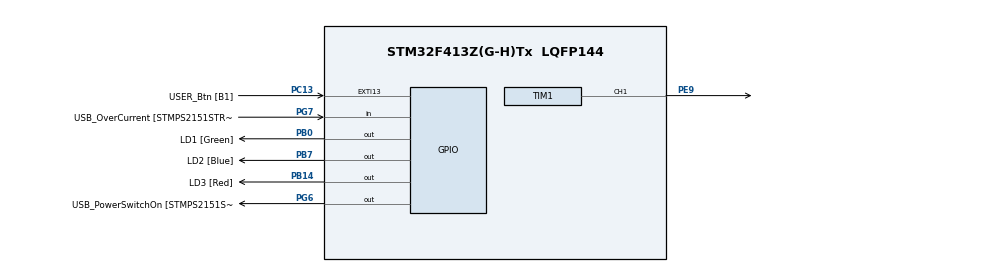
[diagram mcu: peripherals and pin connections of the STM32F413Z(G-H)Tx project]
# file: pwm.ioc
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Mcu.Family=STM32F4
Mcu.Name=STM32F413Z(G-H)Tx
Mcu.Package=LQFP144
NVIC.PriorityGroup=NVIC_PRIORITYGROUP_4
PA10.GPIO_Label=USB_ID
PA10.Signal=USB_OTG_FS_ID
PA11.GPIO_Label=USB_DM
PA11.Signal=USB_OTG_FS_DM
PA12.GPIO_Label=USB_DP
PA12.Signal=USB_OTG_FS_DP
PA13.GPIO_Label=TMS
PA13.Mode=Trace_Asynchronous_SW
PA13.Signal=SYS_JTMS-SWDIO
PA14.GPIO_Label=TCK
PA14.Mode=Trace_Asynchronous_SW
PA14.Signal=SYS_JTCK-SWCLK
PA8.GPIO_Label=USB_SOF [TP1]
PA8.Signal=USB_OTG_FS_SOF
PA9.GPIO_Label=USB_VBUS
PA9.Signal=USB_OTG_FS_VBUS
PB0.GPIO_Label=LD1 [Green]
PB0.Signal=GPIO_Output
PB14.GPIO_Label=LD3 [Red]
PB14.Signal=GPIO_Output
PB3.GPIO_Label=SWO
PB3.Mode=Trace_Asynchronous_SW
PB3.Signal=SYS_JTDO-SWO
PB7.GPIO_Label=LD2 [Blue]
PB7.Signal=GPIO_Output
PC13.GPIO_Label=USER_Btn [B1]
PC13.Signal=GPXTI13
PC14-OSC32_IN.Signal=RCC_OSC32_IN
PC15-OSC32_OUT.Signal=RCC_OSC32_OUT
PD8.GPIO_Label=STLK_RX [STM32F103CBT6_PA3]
PD8.Signal=USART3_TX
PD9.GPIO_Label=STLK_TX [STM32F103CBT6_PA2]
PD9.Signal=USART3_RX
PE9.Signal=S_TIM1_CH1
PG6.GPIO_Label=USB_PowerSwitchOn [STMPS2151STR_EN]
PG6.Signal=GPIO_Output
PG7.GPIO_Label=USB_OverCurrent [STMPS2151STR_FAULT]
PG7.Signal=GPIO_Input
PH0\ -\ OSC_IN.GPIO_Label=MCO
PH0\ -\ OSC_IN.Mode=HSE-External-Oscillator
PH0\ -\ OSC_IN.Signal=RCC_OSC_IN
PH1\ -\ OSC_OUT.Mode=HSE-External-Oscillator
PH1\ -\ OSC_OUT.Signal=RCC_OSC_OUT
ProjectManager.HeapSize=0x2000
ProjectManager.StackSize=0x4000
ProjectManager.TargetToolchain=EWARM V8.32
RCC.48MHZClocksFreq_Value=24000000
RCC.AHBFreq_Value=100000000
RCC.APB1CLKDivider=RCC_HCLK_DIV2
RCC.APB1Freq_Value=50000000
RCC.APB1TimFreq_Value=100000000
RCC.APB2Freq_Value=100000000
RCC.APB2TimFreq_Value=100000000
RCC.CortexFreq_Value=100000000
RCC.HCLKFreq_Value=100000000
RCC.HSE_VALUE=8000000
RCC.HSI_VALUE=16000000
RCC.PLLM=4
RCC.PLLMUL=RCC_PLL_MUL9
RCC.PLLN=100
RCC.PLLSourceVirtual=RCC_PLLSOURCE_HSE
RCC.PRESCALERUSB=RCC_USBCLKSOURCE_PLL_DIV1_5
RCC.SYSCLKFreq_VALUE=100000000
RCC.SYSCLKSource=RCC_SYSCLKSOURCE_PLLCLK
RCC.SYSCLKSourceVirtual=RCC_SYSCLKSOURCE_PLLCLK
RCC.USBFreq_Value=100000000
RCC.VCOOutputFreq_Value=200000000
SH.S_TIM1_CH1.0=TIM1_CH1,PWM Generation1 CH1
TIM1.Channel-PWM\ Generation1\ CH1=TIM_CHANNEL_1
TIM1.Period=9999
TIM1.Prescaler=199
VP_TIM1_VS_ClockSourceINT.Mode=Internal
board=NUCLEO-F413ZH

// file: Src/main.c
/* USER CODE BEGIN Header */
/**
  ******************************************************************************
  * @file           : main.c
  * @brief          : Main program body
  ******************************************************************************
  * @attention
  *
  * <h2><center>&copy; Copyright (c) 2020 STMicroelectronics.
  * All rights reserved.</center></h2>
  *
  * This software component is licensed by ST under BSD 3-Clause license,
  * the "License"; You may not use this file except in compliance with the
  * License. You may obtain a copy of the License at:
  *                        opensource.org/licenses/BSD-3-Clause
  *
  ******************************************************************************
  */
/* USER CODE END Header */

#include "main.h"

void SystemClock_Config(void);
static void MX_GPIO_Init(void);
static void MX_TIM1_Init(void);

int main(void)
{

  /* MCU Configuration--------------------------------------------------------*/

  /* Reset of all peripherals, Initializes the Flash interface and the Systick. */

  LL_APB2_GRP1_EnableClock(LL_APB2_GRP1_PERIPH_SYSCFG);
  LL_APB1_GRP1_EnableClock(LL_APB1_GRP1_PERIPH_PWR);

  NVIC_SetPriorityGrouping(NVIC_PRIORITYGROUP_4);

  /* System interrupt init*/

  /* Configure the system clock */
  SystemClock_Config();

  /* Initialize all configured peripherals */
  MX_GPIO_Init();
  MX_TIM1_Init();
  /* USER CODE BEGIN 2 */
  LL_TIM_CC_EnableChannel(TIM1, LL_TIM_CHANNEL_CH1);
  LL_TIM_EnableCounter(TIM1);
  LL_TIM_EnableAllOutputs(TIM1);
  /* USER CODE END 2 */

  /* Infinite loop */
  while (1)
  {

    /* USER CODE BEGIN 3 */
    LL_TIM_OC_SetCompareCH1(TIM1, 249);
    LL_mDelay(1000);
    LL_TIM_OC_SetCompareCH1(TIM1, 1199);
    LL_mDelay(1000);
  }
  /* USER CODE END 3 */
}

void SystemClock_Config(void)
{
  LL_FLASH_SetLatency(LL_FLASH_LATENCY_3);

  if(LL_FLASH_GetLatency() != LL_FLASH_LATENCY_3)
  {
  Error_Handler();
  }
  LL_PWR_SetRegulVoltageScaling(LL_PWR_REGU_VOLTAGE_SCALE1);
  LL_RCC_HSE_Enable();

   /* Wait till HSE is ready */
  while(LL_RCC_HSE_IsReady() != 1)
  {

  }
  LL_RCC_PLL_ConfigDomain_SYS(LL_RCC_PLLSOURCE_HSE, LL_RCC_PLLM_DIV_4, 100, LL_RCC_PLLP_DIV_2);
  LL_RCC_PLL_Enable();

   /* Wait till PLL is ready */
  while(LL_RCC_PLL_IsReady() != 1)
  {

  }
  LL_RCC_SetAHBPrescaler(LL_RCC_SYSCLK_DIV_1);
  LL_RCC_SetAPB1Prescaler(LL_RCC_APB1_DIV_2);
  LL_RCC_SetAPB2Prescaler(LL_RCC_APB2_DIV_1);
  LL_RCC_SetSysClkSource(LL_RCC_SYS_CLKSOURCE_PLL);

   /* Wait till System clock is ready */
  while(LL_RCC_GetSysClkSource() != LL_RCC_SYS_CLKSOURCE_STATUS_PLL)
  {

  }
  LL_Init1msTick(100000000);
  LL_SYSTICK_SetClkSource(LL_SYSTICK_CLKSOURCE_HCLK);
  LL_SetSystemCoreClock(100000000);
  LL_RCC_SetTIMPrescaler(LL_RCC_TIM_PRESCALER_TWICE);
}

static void MX_TIM1_Init(void)
{

  LL_TIM_InitTypeDef TIM_InitStruct = {0};
  LL_TIM_OC_InitTypeDef TIM_OC_InitStruct = {0};
  LL_TIM_BDTR_InitTypeDef TIM_BDTRInitStruct = {0};

  LL_GPIO_InitTypeDef GPIO_InitStruct = {0};

  /* Peripheral clock enable */
  LL_APB2_GRP1_EnableClock(LL_APB2_GRP1_PERIPH_TIM1);

  TIM_InitStruct.Prescaler = 199;
  TIM_InitStruct.CounterMode = LL_TIM_COUNTERMODE_UP;
  TIM_InitStruct.Autoreload = 9999;
  TIM_InitStruct.ClockDivision = LL_TIM_CLOCKDIVISION_DIV1;
  TIM_InitStruct.RepetitionCounter = 0;
  LL_TIM_Init(TIM1, &TIM_InitStruct);
  LL_TIM_DisableARRPreload(TIM1);
  LL_TIM_SetClockSource(TIM1, LL_TIM_CLOCKSOURCE_INTERNAL);
  LL_TIM_OC_EnablePreload(TIM1, LL_TIM_CHANNEL_CH1);
  TIM_OC_InitStruct.OCMode = LL_TIM_OCMODE_PWM1;
  TIM_OC_InitStruct.OCState = LL_TIM_OCSTATE_DISABLE;
  TIM_OC_InitStruct.OCNState = LL_TIM_OCSTATE_DISABLE;
  TIM_OC_InitStruct.CompareValue = 0;
  TIM_OC_InitStruct.OCPolarity = LL_TIM_OCPOLARITY_HIGH;
  TIM_OC_InitStruct.OCNPolarity = LL_TIM_OCPOLARITY_HIGH;
  TIM_OC_InitStruct.OCIdleState = LL_TIM_OCIDLESTATE_LOW;
  TIM_OC_InitStruct.OCNIdleState = LL_TIM_OCIDLESTATE_LOW;
  LL_TIM_OC_Init(TIM1, LL_TIM_CHANNEL_CH1, &TIM_OC_InitStruct);
  LL_TIM_OC_DisableFast(TIM1, LL_TIM_CHANNEL_CH1);
  LL_TIM_SetTriggerOutput(TIM1, LL_TIM_TRGO_RESET);
  LL_TIM_DisableMasterSlaveMode(TIM1);
  TIM_BDTRInitStruct.OSSRState = LL_TIM_OSSR_DISABLE;
  TIM_BDTRInitStruct.OSSIState = LL_TIM_OSSI_DISABLE;
  TIM_BDTRInitStruct.LockLevel = LL_TIM_LOCKLEVEL_OFF;
  TIM_BDTRInitStruct.DeadTime = 0;
  TIM_BDTRInitStruct.BreakState = LL_TIM_BREAK_DISABLE;
  TIM_BDTRInitStruct.BreakPolarity = LL_TIM_BREAK_POLARITY_HIGH;
  TIM_BDTRInitStruct.AutomaticOutput = LL_TIM_AUTOMATICOUTPUT_DISABLE;
  LL_TIM_BDTR_Init(TIM1, &TIM_BDTRInitStruct);
  LL_AHB1_GRP1_EnableClock(LL_AHB1_GRP1_PERIPH_GPIOE);
  /**TIM1 GPIO Configuration
  PE9   ------> TIM1_CH1
  */
  GPIO_InitStruct.Pin = LL_GPIO_PIN_9;
  GPIO_InitStruct.Mode = LL_GPIO_MODE_ALTERNATE;
  GPIO_InitStruct.Speed = LL_GPIO_SPEED_FREQ_LOW;
  GPIO_InitStruct.OutputType = LL_GPIO_OUTPUT_PUSHPULL;
  GPIO_InitStruct.Pull = LL_GPIO_PULL_NO;
  GPIO_InitStruct.Alternate = LL_GPIO_AF_1;
  LL_GPIO_Init(GPIOE, &GPIO_InitStruct);

}

static void MX_GPIO_Init(void)
{
  LL_EXTI_InitTypeDef EXTI_InitStruct = {0};
  LL_GPIO_InitTypeDef GPIO_InitStruct = {0};

  /* GPIO Ports Clock Enable */
  LL_AHB1_GRP1_EnableClock(LL_AHB1_GRP1_PERIPH_GPIOC);
  LL_AHB1_GRP1_EnableClock(LL_AHB1_GRP1_PERIPH_GPIOH);
  LL_AHB1_GRP1_EnableClock(LL_AHB1_GRP1_PERIPH_GPIOB);
  LL_AHB1_GRP1_EnableClock(LL_AHB1_GRP1_PERIPH_GPIOE);
  LL_AHB1_GRP1_EnableClock(LL_AHB1_GRP1_PERIPH_GPIOD);
  LL_AHB1_GRP1_EnableClock(LL_AHB1_GRP1_PERIPH_GPIOG);
  LL_AHB1_GRP1_EnableClock(LL_AHB1_GRP1_PERIPH_GPIOA);

  /**/
  LL_GPIO_ResetOutputPin(GPIOB, LD1_Pin|LD3_Pin|LD2_Pin);

  /**/
  LL_GPIO_ResetOutputPin(USB_PowerSwitchOn_GPIO_Port, USB_PowerSwitchOn_Pin);

  /**/
  LL_SYSCFG_SetEXTISource(LL_SYSCFG_EXTI_PORTC, LL_SYSCFG_EXTI_LINE13);

  /**/
  EXTI_InitStruct.Line_0_31 = LL_EXTI_LINE_13;
  EXTI_InitStruct.LineCommand = ENABLE;
  EXTI_InitStruct.Mode = LL_EXTI_MODE_IT;
  EXTI_InitStruct.Trigger = LL_EXTI_TRIGGER_RISING;
  LL_EXTI_Init(&EXTI_InitStruct);

  /**/
  LL_GPIO_SetPinPull(USER_Btn_GPIO_Port, USER_Btn_Pin, LL_GPIO_PULL_NO);

  /**/
  LL_GPIO_SetPinMode(USER_Btn_GPIO_Port, USER_Btn_Pin, LL_GPIO_MODE_INPUT);

  /**/
  GPIO_InitStruct.Pin = LD1_Pin|LD3_Pin|LD2_Pin;
  GPIO_InitStruct.Mode = LL_GPIO_MODE_OUTPUT;
  GPIO_InitStruct.Speed = LL_GPIO_SPEED_FREQ_LOW;
  GPIO_InitStruct.OutputType = LL_GPIO_OUTPUT_PUSHPULL;
  GPIO_InitStruct.Pull = LL_GPIO_PULL_NO;
  LL_GPIO_Init(GPIOB, &GPIO_InitStruct);

  /**/
  GPIO_InitStruct.Pin = STLK_RX_Pin|STLK_TX_Pin;
  GPIO_InitStruct.Mode = LL_GPIO_MODE_ALTERNATE;
  GPIO_InitStruct.Speed = LL_GPIO_SPEED_FREQ_VERY_HIGH;
  GPIO_InitStruct.OutputType = LL_GPIO_OUTPUT_PUSHPULL;
  GPIO_InitStruct.Pull = LL_GPIO_PULL_NO;
  GPIO_InitStruct.Alternate = LL_GPIO_AF_7;
  LL_GPIO_Init(GPIOD, &GPIO_InitStruct);

  /**/
  GPIO_InitStruct.Pin = USB_PowerSwitchOn_Pin;
  GPIO_InitStruct.Mode = LL_GPIO_MODE_OUTPUT;
  GPIO_InitStruct.Speed = LL_GPIO_SPEED_FREQ_LOW;
  GPIO_InitStruct.OutputType = LL_GPIO_OUTPUT_PUSHPULL;
  GPIO_InitStruct.Pull = LL_GPIO_PULL_NO;
  LL_GPIO_Init(USB_PowerSwitchOn_GPIO_Port, &GPIO_InitStruct);

  /**/
  GPIO_InitStruct.Pin = USB_OverCurrent_Pin;
  GPIO_InitStruct.Mode = LL_GPIO_MODE_INPUT;
  GPIO_InitStruct.Pull = LL_GPIO_PULL_NO;
  LL_GPIO_Init(USB_OverCurrent_GPIO_Port, &GPIO_InitStruct);

  /**/
  GPIO_InitStruct.Pin = USB_SOF_Pin|USB_ID_Pin|USB_DM_Pin|USB_DP_Pin;
  GPIO_InitStruct.Mode = LL_GPIO_MODE_ALTERNATE;
  GPIO_InitStruct.Speed = LL_GPIO_SPEED_FREQ_VERY_HIGH;
  GPIO_InitStruct.OutputType = LL_GPIO_OUTPUT_PUSHPULL;
  GPIO_InitStruct.Pull = LL_GPIO_PULL_NO;
  GPIO_InitStruct.Alternate = LL_GPIO_AF_10;
  LL_GPIO_Init(GPIOA, &GPIO_InitStruct);

}

void Error_Handler(void)
{
}

/************************ (C) COPYRIGHT STMicroelectronics *****END OF FILE****/
